VERSION ""

NS_ :

BS_:

BU_:

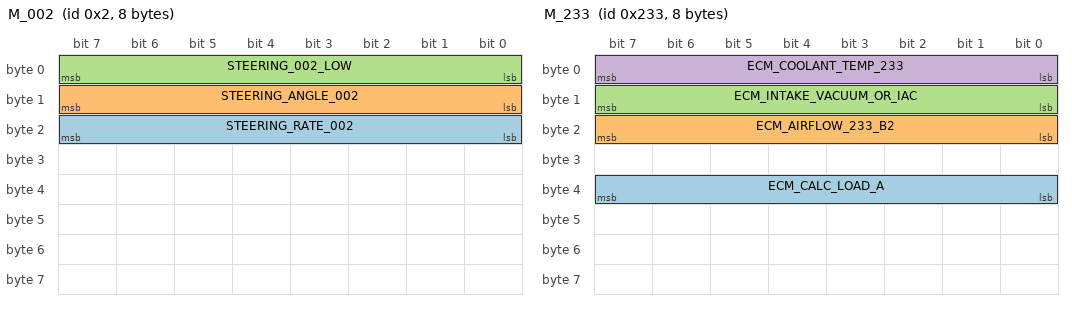
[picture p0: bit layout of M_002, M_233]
BO_ 2 M_002: 8 Vector__XXX
 SG_ STEERING_RATE_002 : 23|8@0+ (1,0) [0|0] "" Vector__XXX
 SG_ STEERING_ANGLE_002 : 15|8@0+ (1,0) [0|0] "" Vector__XXX
 SG_ STEERING_002_LOW : 7|8@0+ (1,0) [0|0] "" Vector__XXX

BO_ 505 M_1F9: 8 Vector__XXX
 SG_ ECM_RPM : 23|16@0+ (0.125,0.0) [0.0|7000.0] "rpm" Vector__XXX
 SG_ COOLING_FAN_1F9_0 : 7|8@0+ (1,0) [0|0] "" Vector__XXX

BO_ 561 M_231: 8 Vector__XXX
 SG_ ECM_ENGINE_STATE_B : 31|8@0+ (1,0) [0|0] "enum" Vector__XXX
 SG_ ECM_ENGINE_STATE_A : 7|8@0+ (1,0) [0|0] "enum" Vector__XXX

BO_ 563 M_233: 8 Vector__XXX
 SG_ ECM_CALC_LOAD_A : 39|8@0+ (1,0) [0|0] "" Vector__XXX
 SG_ ECM_AIRFLOW_233_B2 : 23|8@0+ (1,0) [0|0] "" Vector__XXX
 SG_ ECM_INTAKE_VACUUM_OR_IAC : 15|8@0+ (1,0) [0|0] "" Vector__XXX
 SG_ ECM_COOLANT_TEMP_233 : 7|8@0+ (1,-50) [-10.0|130.0] "degC" Vector__XXX

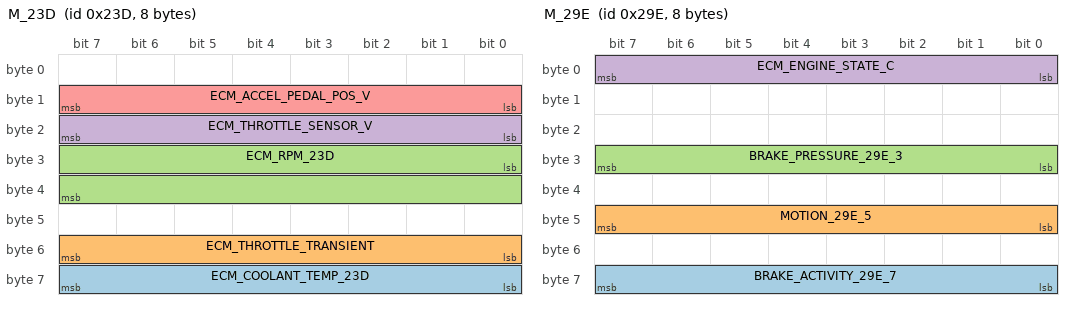
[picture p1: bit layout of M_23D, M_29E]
BO_ 573 M_23D: 8 Vector__XXX
 SG_ ECM_COOLANT_TEMP_23D : 63|8@0+ (1,-50) [-10.0|130.0] "degC" Vector__XXX
 SG_ ECM_THROTTLE_TRANSIENT : 55|8@0+ (1,0) [0|0] "" Vector__XXX
 SG_ ECM_RPM_23D : 24|16@1+ (3.125,0.0) [0.0|8000.0] "rpm" Vector__XXX
 SG_ ECM_THROTTLE_SENSOR_V : 23|8@0+ (0.01341,0.684) [0.6|4.8] "V" Vector__XXX
 SG_ ECM_ACCEL_PEDAL_POS_V : 15|8@0+ (0.01485,0.795) [0.7|4.8] "V" Vector__XXX

BO_ 640 M_280: 8 Vector__XXX
 SG_ MOTION_SIGNAL_280_5 : 47|8@0+ (1,0) [0|0] "" Vector__XXX

BO_ 644 M_284: 8 Vector__XXX
 SG_ WHEEL_SPEED_PAIR_A : 15|16@0+ (1,0) [0|0] "" Vector__XXX

BO_ 645 M_285: 8 Vector__XXX
 SG_ WHEEL_SPEED_PAIR_B : 15|16@0+ (1,0) [0|0] "" Vector__XXX

BO_ 670 M_29E: 8 Vector__XXX
 SG_ BRAKE_ACTIVITY_29E_7 : 63|8@0+ (1,0) [0|0] "" Vector__XXX
 SG_ MOTION_29E_5 : 47|8@0+ (1,0) [0|0] "" Vector__XXX
 SG_ BRAKE_PRESSURE_29E_3 : 31|8@0+ (1,0) [0|0] "" Vector__XXX
 SG_ ECM_ENGINE_STATE_C : 7|8@0+ (1,0) [0|0] "enum" Vector__XXX

BO_ 721 M_2D1: 8 Vector__XXX
 SG_ MOTION_SIGNAL_2D1_1 : 15|8@0+ (1,0) [0|0] "" Vector__XXX

BO_ 852 M_354: 8 Vector__XXX
 SG_ MOTION_SIGNAL_354_1 : 15|8@0+ (1,0) [0|0] "" Vector__XXX

BO_ 856 M_358: 8 Vector__XXX
 SG_ HVAC_BLOWER_LIGHTING_358_1 : 15|8@0+ (1,0) [0|0] "" Vector__XXX

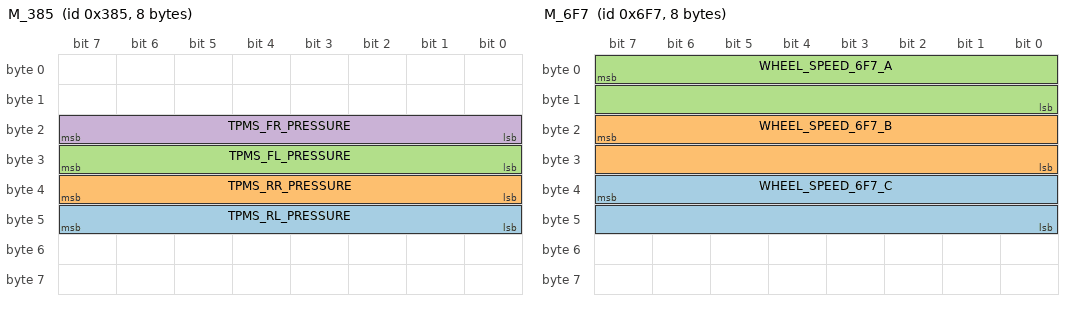
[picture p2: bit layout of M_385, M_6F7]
BO_ 901 M_385: 8 Vector__XXX
 SG_ TPMS_RL_PRESSURE : 47|8@0+ (0.25,0.0) [0.0|80.0] "psi" Vector__XXX
 SG_ TPMS_RR_PRESSURE : 39|8@0+ (0.25,0.0) [0.0|80.0] "psi" Vector__XXX
 SG_ TPMS_FL_PRESSURE : 31|8@0+ (0.25,0.0) [0.0|80.0] "psi" Vector__XXX
 SG_ TPMS_FR_PRESSURE : 23|8@0+ (0.25,0.0) [0.0|80.0] "psi" Vector__XXX

BO_ 1361 M_551: 8 Vector__XXX
 SG_ ECM_COOLANT_TEMP : 7|8@0+ (1,-40) [-10.0|130.0] "degC" Vector__XXX

BO_ 1424 M_590: 8 Vector__XXX
 SG_ MOTION_SIGNAL_590_5 : 47|8@0+ (1,0) [0|0] "" Vector__XXX
 SG_ MOTION_SIGNAL_590_2 : 23|8@0+ (1,0) [0|0] "" Vector__XXX

BO_ 1573 M_625: 8 Vector__XXX
 SG_ POWER_STATE_625_3 : 31|8@0+ (1,0) [0|0] "" Vector__XXX
 SG_ AC_COMPRESSOR_STATE : 15|8@0+ (1,0) [0|0] "" Vector__XXX

BO_ 1783 M_6F7: 8 Vector__XXX
 SG_ WHEEL_SPEED_6F7_C : 39|16@0+ (0.0625,0.0) [0.0|250.0] "km/h" Vector__XXX
 SG_ WHEEL_SPEED_6F7_B : 23|16@0+ (0.0625,0.0) [0.0|250.0] "km/h" Vector__XXX
 SG_ WHEEL_SPEED_6F7_A : 7|16@0+ (0.0625,0.0) [0.0|250.0] "km/h" Vector__XXX

CM_ BO_ 2 "Xterra 0x2 (draft from bindings.yaml)";
CM_ SG_ 2 STEERING_RATE_002 "confidence=low; Renamed from MOTION_002_2. Pairs with STEERING_ANGLE_002 (0x002:0-1):";
CM_ SG_ 2 STEERING_ANGLE_002 "confidence=low; Renamed from GEAR_OR_MOTION_002_1. The old reading (\"stationary 254 /";
CM_ SG_ 2 STEERING_002_LOW "confidence=low; Reinterpreted from \"vehicle motion state\" to the low byte of a 16-bit";
CM_ BO_ 505 "Xterra 0x1F9 (draft from bindings.yaml)";
CM_ SG_ 505 ECM_RPM "confidence=confirmed; Confirmed engine RPM, 16-bit at 8 counts/rpm on the ~100 Hz 0x1F9 frame.";
CM_ SG_ 505 COOLING_FAN_1F9_0 "confidence=high; Cooling-fan status on the ECM 0x1F9 frame, byte 0: base bit 0x20";
CM_ BO_ 561 "Xterra 0x231 (draft from bindings.yaml)";
CM_ SG_ 561 ECM_ENGINE_STATE_B "confidence=high; Cross-broadcast duplicate.";
CM_ SG_ 561 ECM_ENGINE_STATE_A "confidence=high; State enum, useful as an anomaly-detection input: an unexpected";
CM_ BO_ 563 "Xterra 0x233 (draft from bindings.yaml)";
CM_ SG_ 563 ECM_CALC_LOAD_A "confidence=medium; Direction (high cranking, mid idle, low at sustained throttle) is";
CM_ SG_ 563 ECM_AIRFLOW_233_B2 "confidence=medium; Do not pin a scale on the strength of the correlation alone — that is the";
CM_ SG_ 563 ECM_INTAKE_VACUUM_OR_IAC "confidence=high; A/C-load drop in the second session promotes this from \"vacuum or IAC\"";
CM_ SG_ 563 ECM_COOLANT_TEMP_233 "confidence=high; Engine coolant temperature, published on three frames with two offset";
CM_ BO_ 573 "Xterra 0x23D (draft from bindings.yaml)";
CM_ SG_ 573 ECM_COOLANT_TEMP_23D "confidence=high; Engine coolant temperature, published on three frames with two offset";
CM_ SG_ 573 ECM_THROTTLE_TRANSIENT "confidence=high; Three physical-action sessions agree, including a full engine-off";
CM_ SG_ 573 ECM_RPM_23D "confidence=high; 0x1F9 stores rpm x 8; this field stores rpm x 0.32, so it carries the";
CM_ SG_ 573 ECM_THROTTLE_SENSOR_V "confidence=confirmed; Previously unbound — byte 2 was being consumed as the low half of the";
CM_ SG_ 573 ECM_ACCEL_PEDAL_POS_V "confidence=confirmed; Renamed twice: ECM_ENGINE_REV_LEVEL → ECM_AIRFLOW_PROXY_23D → this. The";
CM_ BO_ 640 "Xterra 0x280 (draft from bindings.yaml)";
CM_ SG_ 640 MOTION_SIGNAL_280_5 "confidence=hypothesized; Strong motion-correlated; type TBD.";
CM_ BO_ 644 "Xterra 0x284 (draft from bindings.yaml)";
CM_ SG_ 644 WHEEL_SPEED_PAIR_A "confidence=hypothesized; RETRACTED 2026-08-07: the inventory comparison established only that";
CM_ BO_ 645 "Xterra 0x285 (draft from bindings.yaml)";
CM_ SG_ 645 WHEEL_SPEED_PAIR_B "confidence=hypothesized; See WHEEL_SPEED_PAIR_A retraction; not a wheel-speed binding.";
CM_ BO_ 670 "Xterra 0x29E (draft from bindings.yaml)";
CM_ SG_ 670 BRAKE_ACTIVITY_29E_7 "confidence=high; Brake-dominant driver-demand / pedal-activity composite on the ~20 ms";
CM_ SG_ 670 MOTION_29E_5 "confidence=high; Reinterpreted from \"vehicle motion\" to \"calculated engine load /";
CM_ SG_ 670 BRAKE_PRESSURE_29E_3 "confidence=high; Foot-brake-applied signal on the ~20 ms ABS frame: ~0 released,";
CM_ SG_ 670 ECM_ENGINE_STATE_C "confidence=high; Cross-broadcast duplicate.";
CM_ BO_ 721 "Xterra 0x2D1 (draft from bindings.yaml)";
CM_ SG_ 721 MOTION_SIGNAL_2D1_1 "confidence=hypothesized; Strong motion-correlated candidate. Likely vehicle speed (8-bit) OR";
CM_ BO_ 852 "Xterra 0x354 (draft from bindings.yaml)";
CM_ SG_ 852 MOTION_SIGNAL_354_1 "confidence=hypothesized; 37ms cadence is unusual — typically used for transmission or 4WD";
CM_ BO_ 856 "Xterra 0x358 (draft from bindings.yaml)";
CM_ SG_ 856 HVAC_BLOWER_LIGHTING_358_1 "confidence=medium; Bit-packed HVAC-blower + exterior-lighting status byte (not a scalar):";
CM_ BO_ 901 "Xterra 0x385 (draft from bindings.yaml)";
CM_ SG_ 901 TPMS_RL_PRESSURE "confidence=hypothesized; Candidate layout from a working QM5/Koleos CAN display: byte 2 FR,";
CM_ SG_ 901 TPMS_RR_PRESSURE "confidence=hypothesized; Candidate layout from a working QM5/Koleos CAN display: byte 2 FR,";
CM_ SG_ 901 TPMS_FL_PRESSURE "confidence=hypothesized; Candidate layout from a working QM5/Koleos CAN display: byte 2 FR,";
CM_ SG_ 901 TPMS_FR_PRESSURE "confidence=hypothesized; Candidate layout from a working QM5/Koleos CAN display: byte 2 FR,";
CM_ BO_ 1361 "Xterra 0x551 (draft from bindings.yaml)";
CM_ SG_ 1361 ECM_COOLANT_TEMP "confidence=confirmed; Strong candidate. ELM327 Mode 01 PID 0x05 (engine coolant temp) will";
CM_ BO_ 1424 "Xterra 0x590 (draft from bindings.yaml)";
CM_ SG_ 1424 MOTION_SIGNAL_590_5 "confidence=hypothesized; Paired with MOTION_SIGNAL_590_2; same ID, same cadence.";
CM_ SG_ 1424 MOTION_SIGNAL_590_2 "confidence=hypothesized; On the slow 92ms body bus, so likely a BCM-aware signal (odometer";
CM_ BO_ 1573 "Xterra 0x625 (draft from bindings.yaml)";
CM_ SG_ 1573 POWER_STATE_625_3 "confidence=medium; Plausible ignition/power state byte. 157 = key-on-engine-off,";
CM_ SG_ 1573 AC_COMPRESSOR_STATE "confidence=high; A/C compressor commanded state: 0 = off, ~128 = engaged, with";
CM_ BO_ 1783 "Xterra 0x6F7 (draft from bindings.yaml)";
CM_ SG_ 1783 WHEEL_SPEED_6F7_C "confidence=high; One of three 16-bit speed fields on the ABS 0x6F7 frame (bytes 0-1,";
CM_ SG_ 1783 WHEEL_SPEED_6F7_B "confidence=high; One of three 16-bit speed fields on the ABS 0x6F7 frame (bytes 0-1,";
CM_ SG_ 1783 WHEEL_SPEED_6F7_A "confidence=high; One of three 16-bit speed fields on the ABS 0x6F7 frame (bytes 0-1,";
